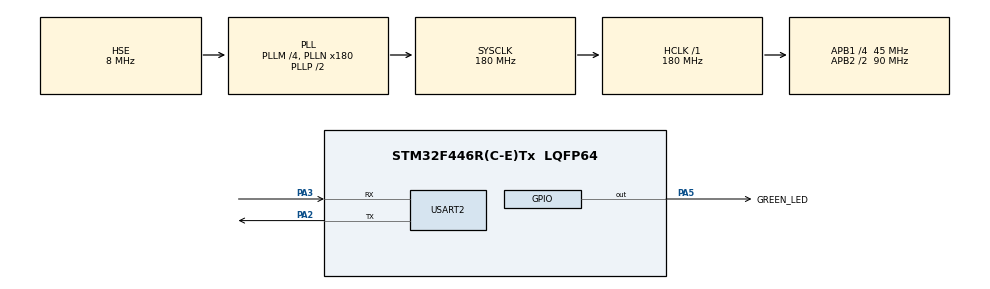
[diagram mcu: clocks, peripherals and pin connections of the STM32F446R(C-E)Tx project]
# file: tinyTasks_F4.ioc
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Mcu.Family=STM32F4
Mcu.Name=STM32F446R(C-E)Tx
Mcu.Package=LQFP64
NVIC.PriorityGroup=NVIC_PRIORITYGROUP_4
NVIC.TIM5_IRQn=true\:15\:0\:false\:false\:true\:false\:true\:true
NVIC.TimeBase=TIM5_IRQn
NVIC.TimeBaseIP=TIM5
PA13.Mode=Serial_Wire
PA13.Signal=SYS_JTMS-SWDIO
PA14.Mode=Serial_Wire
PA14.Signal=SYS_JTCK-SWCLK
PA2.Mode=Asynchronous
PA2.Signal=USART2_TX
PA3.Mode=Asynchronous
PA3.Signal=USART2_RX
PA5.GPIO_Label=GREEN_LED
PA5.Signal=GPIO_Output
PH0-OSC_IN.Mode=HSE-External-Oscillator
PH0-OSC_IN.Signal=RCC_OSC_IN
PH1-OSC_OUT.Mode=HSE-External-Oscillator
PH1-OSC_OUT.Signal=RCC_OSC_OUT
ProjectManager.HeapSize=0x2000
ProjectManager.StackSize=0x2000
ProjectManager.TargetToolchain=Makefile
RCC.AHBFreq_Value=180000000
RCC.APB1CLKDivider=RCC_HCLK_DIV4
RCC.APB1Freq_Value=45000000
RCC.APB1TimFreq_Value=90000000
RCC.APB2CLKDivider=RCC_HCLK_DIV2
RCC.APB2Freq_Value=90000000
RCC.APB2TimFreq_Value=180000000
RCC.CortexFreq_Value=180000000
RCC.HCLKFreq_Value=180000000
RCC.HSE_VALUE=8000000
RCC.PLLM=4
RCC.PLLN=180
RCC.PLLSourceVirtual=RCC_PLLSOURCE_HSE
RCC.SYSCLKFreq_VALUE=180000000
RCC.SYSCLKSource=RCC_SYSCLKSOURCE_PLLCLK
RCC.USBFreq_Value=180000000
RCC.VCOOutputFreq_Value=360000000
USART2.VirtualMode=VM_ASYNC
VP_SYS_VS_tim5.Mode=TIM5
board=custom

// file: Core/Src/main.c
/* USER CODE BEGIN Header */
/**
  ******************************************************************************
  * @file           : main.c
  * @brief          : Main program body
  ******************************************************************************
  * @attention
  *
  * Copyright (c) 2024 STMicroelectronics.
  * All rights reserved.
  *
  * This software is licensed under terms that can be found in the LICENSE file
  * in the root directory of this software component.
  * If no LICENSE file comes with this software, it is provided AS-IS.
  *
  ******************************************************************************
  */
/* USER CODE END Header */
#include "main.h"
#include "usart.h"
#include "gpio.h"

/* USER CODE BEGIN Includes */
#include "stdbool.h"
#include "stdio.h"
#include "stdint.h"
#include "stdarg.h"
#include "string.h"
#include "errno.h"
#include <sys/unistd.h> // For STDOUT_FILENO, STDERR_FILENO
#include "tinyKernel.h"
#include "tinyTasks_types.h"
#include "tinyTasksError.h"
#include "tinyTasks_task.h"
/* USER CODE END Includes */

/* USER CODE BEGIN PV */
  static uint32_t count = 0;

/* USER CODE END PV */

void SystemClock_Config(void);

/* USER CODE BEGIN 0 */
/*retarget printf */
int _write(int file, char *data, int len) {
    // Only write to STDOUT and STDERR
    if ((file != STDOUT_FILENO) && (file != STDERR_FILENO)) {
        errno = EBADF;
        return -1;
    }

    // Transmit data using UART2
    for (int i = 0; i < len; i++) {
        // Wait for the transmit buffer to be empty
        while (!(USART2->SR & USART_SR_TXE));
        // Send the character
        USART2->DR = (uint16_t)data[i];
    }

    // Wait for the transmission of the last byte to complete
    while (!(USART2->SR & USART_SR_TC));

    return len;
}

void task1(void){
  static uint32_t prev_runtime = 0;
    while(1){
    //elapsed time since last run
    uint32_t currentTime = tinyTask_tick_get();
    uint32_t elapsed_time = currentTime - tinyKernel_getTaskLastRunTime();
    printf("Task 1: %d\r\n", elapsed_time);

    }
}
void task2(void){
    static uint32_t prev_runtime = 0;
    while(1){
    //elapsed time since last run
    uint32_t currentTime = tinyTask_tick_get();
    uint32_t elapsed_time = currentTime - tinyKernel_getTaskLastRunTime();
    printf("Task 2: %d\r\n", elapsed_time);

    }
}

/* USER CODE END 0 */

int main(void)
{

  /* MCU Configuration--------------------------------------------------------*/

  /* Reset of all peripherals, Initializes the Flash interface and the Systick. */
  HAL_Init();

  /* Configure the system clock */
  SystemClock_Config();

  /* Initialize all configured peripherals */
  MX_GPIO_Init();
  MX_USART2_UART_Init();
  /* USER CODE BEGIN 2 */
  //  add user tasks
  if(tinyKernel_init() == TINYTASKS_OK){
  tinyKernel_addTask(task1,2000);
  tinyKernel_addTask(task2,3000);
    tinyKernel_run(); // should not return from this
  }else{
    printf("!!! Error initializing tinyKernel !!!\r\n");
  }
  /* USER CODE END 2 */

  /* Infinite loop */
  /* USER CODE BEGIN WHILE */

  while (1)
  {
    HAL_GPIO_TogglePin(GPIOA, GPIO_PIN_5);
    printf("Error should not be here %d\r\n",count++);
    HAL_Delay(500);
    /* USER CODE END WHILE */

  }
}

void SystemClock_Config(void)
{
  RCC_OscInitTypeDef RCC_OscInitStruct = {0};
  RCC_ClkInitTypeDef RCC_ClkInitStruct = {0};

  /** Configure the main internal regulator output voltage
  */
  __HAL_RCC_PWR_CLK_ENABLE();
  __HAL_PWR_VOLTAGESCALING_CONFIG(PWR_REGULATOR_VOLTAGE_SCALE1);

  /** Initializes the RCC Oscillators according to the specified parameters
  * in the RCC_OscInitTypeDef structure.
  */
  RCC_OscInitStruct.OscillatorType = RCC_OSCILLATORTYPE_HSE;
  RCC_OscInitStruct.HSEState = RCC_HSE_ON;
  RCC_OscInitStruct.PLL.PLLState = RCC_PLL_ON;
  RCC_OscInitStruct.PLL.PLLSource = RCC_PLLSOURCE_HSE;
  RCC_OscInitStruct.PLL.PLLM = 4;
  RCC_OscInitStruct.PLL.PLLN = 180;
  RCC_OscInitStruct.PLL.PLLP = RCC_PLLP_DIV2;
  RCC_OscInitStruct.PLL.PLLQ = 2;
  RCC_OscInitStruct.PLL.PLLR = 2;
  if (HAL_RCC_OscConfig(&RCC_OscInitStruct) != HAL_OK)
  {
    Error_Handler();
  }

  /** Activate the Over-Drive mode
  */
  if (HAL_PWREx_EnableOverDrive() != HAL_OK)
  {
    Error_Handler();
  }

  /** Initializes the CPU, AHB and APB buses clocks
  */
  RCC_ClkInitStruct.ClockType = RCC_CLOCKTYPE_HCLK|RCC_CLOCKTYPE_SYSCLK
                              |RCC_CLOCKTYPE_PCLK1|RCC_CLOCKTYPE_PCLK2;
  RCC_ClkInitStruct.SYSCLKSource = RCC_SYSCLKSOURCE_PLLCLK;
  RCC_ClkInitStruct.AHBCLKDivider = RCC_SYSCLK_DIV1;
  RCC_ClkInitStruct.APB1CLKDivider = RCC_HCLK_DIV4;
  RCC_ClkInitStruct.APB2CLKDivider = RCC_HCLK_DIV2;

  if (HAL_RCC_ClockConfig(&RCC_ClkInitStruct, FLASH_LATENCY_5) != HAL_OK)
  {
    Error_Handler();
  }
}

void HAL_TIM_PeriodElapsedCallback(TIM_HandleTypeDef *htim)
{
  if (htim->Instance == TIM5) {
    HAL_IncTick();
  }
}

void Error_Handler(void)
{
  __disable_irq();
  while (1)
  {
  }
}
